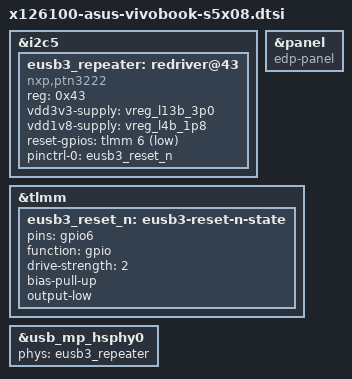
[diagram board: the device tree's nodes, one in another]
// SPDX-License-Identifier: BSD-3-Clause
/*
 * ASUS Vivobook S14 (S5408QA), S14 Flip (TP5408QA), S16 (S5608QA) and
 * S16 Flip (TP5608QA), Snapdragon X X1-26-100 and X1-26-101 (Purwa).
 *
 * The four BIOS images (S5408QA.304, TP5408QA.305, S5608QA.304,
 * TP5608QA.305) carry one DSDT, byte for byte the same apart from its SKU
 * string (\_SB.PSKU: S54, TP54, S56, TP56). The SKU picks the touchpad's
 * _HID, the GPU and audio subsystem IDs, the fan tables and whether the
 * touchscreen is present. Every other device, GPIO and PEP power vote
 * matches the Zenbook 14 UX3480QA's DSDT: the keyboard on IC23 at 0x15,
 * the touchpad, the EC HID device, the lid, Wi-Fi, NVMe, both USB-C ports
 * with their SBU muxes and no retimers, HDMI and sound. So the boards
 * start from that tree.
 *
 * GpioInt pins of 0x100 and up are virtual: pin 0x100 + 0x40 * k is the
 * k-th interrupt after the four summary interrupts in GIO0._CRS, which
 * qcom,pdc-ranges and the X1 PDC map turn into TLMM pins. This gives
 * 0x180 TLMM 67 (keyboard), 0x3C0 TLMM 3 (touchpad), 0x400 TLMM 95 (EC
 * HID), 0x340 TLMM 92 (lid), the pins the UX3480QA tree uses.
 */

#include "x1p42100-asus-zenbook-14-ux3480qa.dts"

/*
 * ASUS lists two USB-A ports. USB3 (usb_mp) in the DSDT holds two eUSB2
 * repeaters, 0x43 and 0x4f on I2C6, reset TLMM 6 and 184. The Zenbook
 * A14 tree pairs 0x4f and TLMM 184 with usb_mp_hsphy1, so 0x43 and TLMM 6
 * serve usb_mp_hsphy0. Supplies as on the other repeaters on this bus.
 *
 * USB4 (usb_2, the camera) keeps its reset on TLMM 7 here but, unlike the
 * UX3480QA's DSDT, names no I2C address, so the inherited repeater at 0x47
 * may sit elsewhere. The ptn3222 driver never talks over I2C; it only
 * switches the supplies and the reset.
 */
&i2c5 {
	eusb3_repeater: redriver@43 {
		compatible = "nxp,ptn3222";
		reg = <0x43>;
		#phy-cells = <0>;

		vdd3v3-supply = <&vreg_l13b_3p0>;
		vdd1v8-supply = <&vreg_l4b_1p8>;

		reset-gpios = <&tlmm 6 GPIO_ACTIVE_LOW>;

		pinctrl-0 = <&eusb3_reset_n>;
		pinctrl-names = "default";
	};
};

/*
 * No retimers: nothing answers on the A14's retimer buses (I2C4 and I2C8
 * in the DSDT's UCS0) on the UX3480QA, and that tree drops their
 * typec-mux nodes. The buses are left with no device, so they go too.
 */
/delete-node/ &i2c3;
/delete-node/ &i2c7;

/*
 * The panel is not in the DSDT: every PCFG/PCEx buffer is Qualcomm's
 * generic OLED placeholder, and the PEP votes for the eDP rails, TLMM 70
 * and 119 and PMC8380_3 GPIO 4 are the UX3480QA's. ASUS sells OLED and
 * IPS panels in these chassis. The generic eDP panel reads its timings
 * from the EDID and, with no backlight node, takes its brightness over
 * the DP AUX channel, as the OLED panels need.
 */
&panel {
	compatible = "edp-panel";
};

&tlmm {
	eusb3_reset_n: eusb3-reset-n-state {
		pins = "gpio6";
		function = "gpio";
		drive-strength = <2>;
		bias-pull-up;
		output-low;
	};
};

&usb_mp_hsphy0 {
	phys = <&eusb3_repeater>;
};
